# CC1314R10 register map
File version: 1.0
CPU: CM33 1.0, other endian, MPU, FPU, 3 interrupt priority bits
Registers are 32-bit, read-write, reset 0x0 unless marked. A register's access mark holds for its fields unless they carry their own. Offsets are from the block's base; [hi:lo] are bit positions; {n}, {i} and the like mark numbered series.

## AUX_SYSIF — AUX System Interface (AUX_SYSIF) is responsible for: - system resource requests, such as power supply, clock and, wakeup requests. - configuration of AUX peripheral operational rates for AUX_SPIM, AUX_MAC, AUX_ANAIF DAC state machine and AUX_TIMER01. - configuration of event synchronization rate for AUX_EVCTL:EVSTAT2 and AUX_EVCTL:EVSTAT3. - configuration of AUX_SCE wakeup vectors that trigger AUX_SCE execution from sleep. Peripheral operational rate for AUX modules mentioned above can either be: - SCE rate, which is configured in AON_PMCTL:AUXSCECLK. - AUX bus rate, which equals SCE rate or SCLK_HF divided by two when MCU domain is active or AUX operational mode is active. AUX_SYSIF also interfaces AON_RTC and AON_BATMON to enable read access to data and sub-second increment control of AON_RTC.
Base 0x580C6000
0x00 OPMODEREQ — Operational Mode Request AUX can operate in three operational modes. Each mode is associated with: - a SCE clock source or rate, given by AON_PMCTL:AUXSCECLK. This rate is termed SCE_RATE. - a system power supply state request. AUX can request powerdown (uLDO) or active (GLDO or DCDC) system power supply state. - a specific system response to an active AUX wakeup flag. The response is dependent on what operational mode is requested. uLDO power supply state offers limited current supply. AUX_SCE cannot use certain peripherals and functions such as AUX_DDI0_OSC, AUX_TDC and AUX_ANAIF ADC interface in this power supply state. Follow these rules: - It is not allowed to change a request until it has been acknowledged through OPMODEACK. - A change in mode request must happen stepwise along this sequence, the direction is irrelevant: PDA - A - LP - PDLP. Failure to follow these rules might result in unexpected behavior and must be avoided.
  [1:0] REQ — [1:0] AUX operational mode request.
    3=PDLP (Powerdown operational mode with wakeup to lowpower mode, characterized by: - Powerdown system power supply state (uLDO) request. - AON_PMCTL:AUXSCECLK.PD_SRC sets the SCE clock frequency (SCE_RATE). - An active wakeup flag overrides the operational mode externally to lowpower (LP) as long as the flag is set.); 2=PDA (Powerdown operational mode with wakeup to active mode, characterized by: - Powerdown system power supply state (uLDO) request. - AON_PMCTL:AUXSCECLK.PD_SRC sets the SCE clock frequency (SCE_RATE). - An active wakeup flag overrides the operational mode externally to active (A) as long as the flag is set.); 1=LP (Lowpower operational mode, characterized by: - Powerdown system power supply state (uLDO) request. - SCE clock frequency (SCE_RATE) equals SCLK_MF. - An active wakeup flag does not change operational mode.); 0=A (Active operational mode, characterized by: - Active system power supply state (GLDO or DCDC) request. - AON_PMCTL:AUXSCECLK.SRC sets the SCE clock frequency (SCE_RATE). - An active wakeup flag does not change operational mode.)
0x04 OPMODEACK — Operational Mode Acknowledgement AUX_SCE program must assume that the current operational mode is the one acknowledged.
  [1:0] ACK ro — [1:0] AUX operational mode acknowledgement.
    3=PDLP (Powerdown operational mode with wakeup to lowpower mode is acknowledged.); 2=PDA (Powerdown operational mode with wakeup to active mode is acknowledged.); 1=LP (Lowpower operational mode is acknowledged.); 0=A (Active operational mode is acknowledged.)
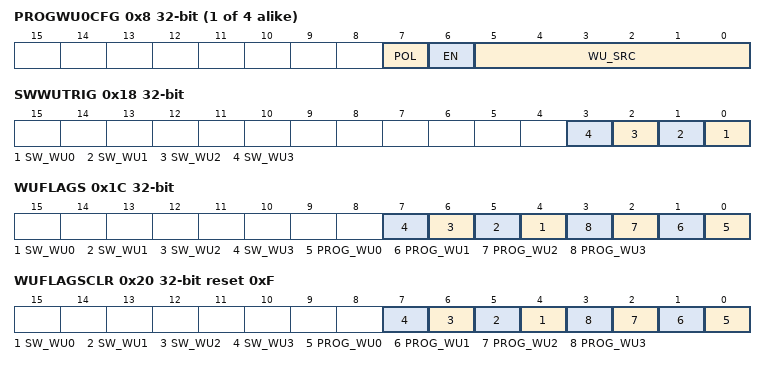
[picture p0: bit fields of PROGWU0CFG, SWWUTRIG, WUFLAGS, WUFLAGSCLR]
{0x8+4i} PROGWU{i}CFG (i=0..3) — Programmable Wakeup {i} Configuration Configure this register to enable a customized AUX wakeup flag. The wakeup flag will be captured by AON_PMCTL which responds according to the current operational mode. You can select WUFLAGS.PROG_WU{i} to trigger execution of a programmable AUX_SCE vector by configuration of VECCFGn. You need to follow the procedure described in WUFLAGSCLR to clear this flag. You need to follow the procedure described in WUGATE to configure it.
  [7] POL — [7:7] Polarity of WU_SRC. The procedure used to clear the wakeup flag decides level or edge sensitivity, see WUFLAGSCLR.PROG_WU{i}.
    1=LOW (The wakeup flag is set when WU_SRC is low or goes low.); 0=HIGH (The wakeup flag is set when WU_SRC is high or goes high.)
  [6] EN — [6:6] Programmable wakeup flag enable. 0: Disable wakeup flag. 1: Enable wakeup flag.
  [5:0] WU_SRC — [5:0] Wakeup source from the asynchronous AUX event bus. Only change WU_SRC when EN is 0 or WUFLAGSCLR.PROG_WU{i} is 1. If you write a non-enumerated value the behavior is identical to NO_EVENT. The written value is returned when read.
    63=NO_EVENT; 61=AUX_SMPH_AUTOTAKE_DONE (AUX_EVCTL:EVSTAT3.AUX_SMPH_AUTOTAKE_DONE); 60=AUX_ADC_FIFO_NOT_EMPTY (AUX_EVCTL:EVSTAT3.AUX_ADC_FIFO_NOT_EMPTY); 59=AUX_ADC_FIFO_ALMOST_FULL (AUX_EVCTL:EVSTAT3.AUX_ADC_FIFO_ALMOST_FULL); 58=AUX_ADC_IRQ (AUX_EVCTL:EVSTAT3.AUX_ADC_IRQ); 57=AUX_ADC_DONE (AUX_EVCTL:EVSTAT3.AUX_ADC_DONE); 56=AUX_ISRC_RESET_N (AUX_EVCTL:EVSTAT3.AUX_ISRC_RESET_N); 55=AUX_TDC_DONE (AUX_EVCTL:EVSTAT3.AUX_TDC_DONE); 54=AUX_TIMER0_EV (AUX_EVCTL:EVSTAT3.AUX_TIMER0_EV); 53=AUX_TIMER1_EV (AUX_EVCTL:EVSTAT3.AUX_TIMER1_EV); 52=AUX_TIMER2_PULSE (AUX_EVCTL:EVSTAT3.AUX_TIMER2_PULSE); {v}=AUX_TIMER2_EV{v-48} (AUX_EVCTL:EVSTAT3.AUX_TIMER2_EV{v-48}) (v=48..51); 47=AUX_COMPB (AUX_EVCTL:EVSTAT2.AUX_COMPB); 46=AUX_COMPA (AUX_EVCTL:EVSTAT2.AUX_COMPA); 45=MCU_OBSMUX1 (AUX_EVCTL:EVSTAT2.MCU_OBSMUX1); 44=MCU_OBSMUX0 (AUX_EVCTL:EVSTAT2.MCU_OBSMUX0); 43=MCU_EV (AUX_EVCTL:EVSTAT2.MCU_EV); 42=ACLK_REF (AUX_EVCTL:EVSTAT2.ACLK_REF); 41=VDDR_RECHARGE (AUX_EVCTL:EVSTAT2.VDDR_RECHARGE); 40=MCU_ACTIVE (AUX_EVCTL:EVSTAT2.MCU_ACTIVE); 39=PWR_DWN (AUX_EVCTL:EVSTAT2.PWR_DWN); 38=SCLK_LF (AUX_EVCTL:EVSTAT2.SCLK_LF); 37=AON_BATMON_TEMP_UPD (AUX_EVCTL:EVSTAT2.AON_BATMON_TEMP_UPD); 36=AON_BATMON_BAT_UPD (AUX_EVCTL:EVSTAT2.AON_BATMON_BAT_UPD); 35=AON_RTC_4KHZ (AUX_EVCTL:EVSTAT2.AON_RTC_4KHZ); 34=AON_RTC_CH2_DLY (AUX_EVCTL:EVSTAT2.AON_RTC_CH2_DLY); 33=AON_RTC_CH2 (AUX_EVCTL:EVSTAT2.AON_RTC_CH2); 32=MANUAL_EV (AUX_EVCTL:EVSTAT2.MANUAL_EV); {v}=AUXIO{v} (AUX_EVCTL:EVSTAT1.AUXIO{v}) (v=16..31); {v}=AUXIO{v} (AUX_EVCTL:EVSTAT0.AUXIO{v}) (v=0..15)
0x18 SWWUTRIG — Software Wakeup Triggers System CPU uses these wakeup flags to perform handshaking with AUX_SCE. The wakeup flags can change the operational mode of AUX and guarantees a non-zero SCE clock rate. AUX_SCE wakeup vectors are configured in VECCFGn.
  [n] SW_WU{n} wo (n=0..3) — [{n}:{n}] Software wakeup {n} trigger. 0: No effect. 1: Set WUFLAGS.SW_WU{n} and trigger AUX wakeup.
0x1C WUFLAGS — Wakeup Flags This register holds the eight AUX wakeup flags. Each flag can cause AUX operational mode to change as given in OPMODEREQ. To clear flag n you must set bit n in WUFLAGSCLR until flag n is read as 0. You must clear bit n in WUFLAGSCLR before flag n can be set again.
  [n+4] SW_WU{n} ro (n=0..3) — [{n+4}:{n+4}] Software wakeup {n} flag. 0: Software wakeup {n} not triggered. 1: Software wakeup {n} triggered.
  [n] PROG_WU{n} ro (n=0..3) — [{n}:{n}] Programmable wakeup {n}. 0: Programmable wakeup {n} not triggered. 1: Programmable wakeup {n} triggered.
0x20 WUFLAGSCLR reset 0xF — Wakeup Flags Clear This register clears AUX wakeup flags WUFLAGS. To clear programmable wakeup flags you must disable the AUX wakeup output first. After the programmable wakeup flags are cleared you must re-enable the AUX wakeup output. Write WUGATE to disable or enable the AUX wakeup output. This procedure is not required when you want to clear a software-triggered wakeup.
  [n+4] SW_WU{n} (n=0..3) — [{n+4}:{n+4}] Clear software wakeup flag {n}. 0: No effect. 1: Clear WUFLAGS.SW_WU{n}. Keep high until WUFLAGS.SW_WU{n} is 0.
  [n] PROG_WU{n} (n=0..3) — [{n}:{n}] Programmable wakeup flag {n}. 0: No effect. 1: Clear WUFLAGS.PROG_WU{n}. Keep high until WUFLAGS.PROG_WU{n} is 0. The wakeup flag becomes edge sensitive if you write PROG_WU{n} to 0 when PROGWU{n}CFG.EN is 1. The wakeup flag becomes level sensitive if you write PROG_WU{n} to 0 when PROGWU{n}CFG.EN is 0, then set PROGWU{n}CFG.EN.
0x24 WUGATE — Wakeup Gate You must disable the AUX wakeup output: - Before you clear a programmable wakeup flag. - Before you change the value of [PROGWUnCFG.EN] or [PROGWUnCFG.WU_SRC]. The AUX wakeup output must be re-enabled after clear operation or programmable wakeup configuration.
  [0] EN — [0:0] Wakeup output enable. 0: Disable AUX wakeup output. 1: Enable AUX wakeup output.
{0x28+4i} VECCFG{i} (i=0..7) — Vector Configuration {i} AUX_SCE wakeup vector {i} configuration
  [3:0] VEC_EV — [3:0] Select trigger event for vector {i}. Non-enumerated values are treated as NONE.
    9=AON_RTC_CH2_DLY (AUX_EVCTL:EVSTAT2.AON_RTC_CH2_DLY); {v}=SW_WU{v-5} (WUFLAGS.SW_WU{v-5}) (v=5..8); {v}=PROG_WU{v-1} (WUFLAGS.PROG_WU{v-1}) (v=1..4); 0=NONE (Vector is disabled.)
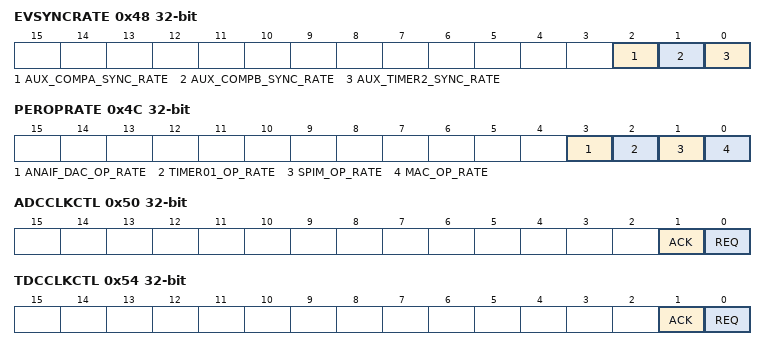
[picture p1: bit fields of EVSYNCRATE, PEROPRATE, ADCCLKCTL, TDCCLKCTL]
0x48 EVSYNCRATE — Event Synchronization Rate Configure synchronization rate for certain events to the synchronous AUX event bus. You must select SCE rate when AUX_SCE uses the event. You must select AUX bus rate when system CPU uses the event. SCE rate equals rate configured in AON_PMCTL:AUXSCECLK. AUX bus rate equals SCE rate, or SCLK_HF divided by two when MCU domain is active.
  [all] fields
    1=BUS_RATE (AUX bus rate); 0=SCE_RATE
  [2] AUX_COMPA_SYNC_RATE — [2:2] Select synchronization rate for AUX_EVCTL:EVSTAT2.AUX_COMPA event.
  [1] AUX_COMPB_SYNC_RATE — [1:1] Select synchronization rate for AUX_EVCTL:EVSTAT2.AUX_COMPB event.
  [0] AUX_TIMER2_SYNC_RATE — [0:0] Select synchronization rate for: - AUX_EVCTL:EVSTAT3.AUX_TIMER2_EV0 - AUX_EVCTL:EVSTAT3.AUX_TIMER2_EV1 - AUX_EVCTL:EVSTAT3.AUX_TIMER2_EV2 - AUX_EVCTL:EVSTAT3.AUX_TIMER2_EV3 - AUX_EVCTL:EVSTAT3.AUX_TIMER2_PULSE
0x4C PEROPRATE — Peripheral Operational Rate Some AUX peripherals are operated at either SCE or at AUX bus rate. You must select SCE rate when AUX_SCE uses such peripheral or an event produced by it. You must select AUX bus rate when system CPU uses such peripheral. SCE rate equals rate configured in AON_PMCTL:AUXSCECLK. AUX bus rate equals SCE rate, or SCLK_HF divided by 2 when MCU domain is active.
  [all] fields
    1=BUS_RATE (AUX bus rate); 0=SCE_RATE
  [3] ANAIF_DAC_OP_RATE — [3:3] Select operational rate for AUX_ANAIF DAC sample clock state machine.
  [2] TIMER01_OP_RATE — [2:2] Select operational rate for AUX_TIMER01.
  [1] SPIM_OP_RATE — [1:1] Select operational rate for AUX_SPIM.
  [0] MAC_OP_RATE — [0:0] Select operational rate for AUX_MAC.
0x50 ADCCLKCTL — ADC Clock Control
  [1] ACK ro — [1:1] Clock acknowledgement. 0: ADC clock is disabled. 1: ADC clock is enabled.
  [0] REQ — [0:0] ADC clock request. 0: Disable ADC clock. 1: Enable ADC clock. Only modify REQ when equal to ACK.
0x54 TDCCLKCTL — TDC Counter Clock Control Controls if the AUX_TDC counter clock source is enabled. These are the recommended steps to configure and request the counter clock: - Ensure that REQ=0 and ACK=0. - Configure clock source in DDI_0_OSC:CTL0.ACLK_TDC_SRC_SEL. - Read DDI_0_OSC:CTL0 to avoid a race condition between previous step and next step. - Set REQ=1 to request the clock. - If DDI_0_OSC:CTL0.ACLK_TDC_SRC_SEL=RCOSC_HF (24 or 48 MHz), wait until ACK=1. - If DDI_0_OSC:CTL0.ACLK_TDC_SRC_SEL=XOSC_HF, wait until ACK=1 and DDI_0_OSC:STAT2.XOSC_HF_FREQGOOD=1. After these steps ACK stays high until REQ=0. It is hence not recommended to reconfigure DDI_0_OSC:CTL0.ACLK_TDC_SRC_SEL when ACK=1. In this case, there will be no indication of when the new clock source selection is ready. These are the recommended steps to stop the counter clock: - Ensure that REQ=1 and ACK=1. - Set REQ=0 to stop the clock. - Wait until ACK=0.
  [1] ACK ro — [1:1] TDC counter clock acknowledgement. 0: TDC counter clock is disabled. 1: TDC counter clock is enabled.
  [0] REQ — [0:0] TDC counter clock request. 0: Disable TDC counter clock. 1: Enable TDC counter clock. Only modify REQ when equal to ACK.
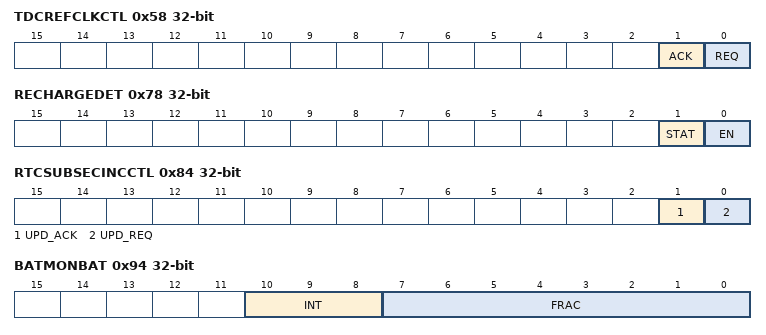
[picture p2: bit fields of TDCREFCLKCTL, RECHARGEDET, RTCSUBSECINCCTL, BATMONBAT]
0x58 TDCREFCLKCTL — TDC Reference Clock Control Controls if the AUX_TDC reference clock source is enabled. These are the recommended steps to configure and request the reference clock: - Ensure that REQ=0 and ACK=0. - Configure clock source in DDI_0_OSC:CTL0.ACLK_REF_SRC_SEL. - Read DDI_0_OSC:CTL0 to avoid a race condition between previous step and next step. - Set REQ=1 to request the clock. - Wait until ACK=1. After these steps ACK stays high until REQ=0. It is hence not recommended to reconfigure DDI_0_OSC:CTL0.ACLK_REF_SRC_SEL when ACK=1. In this case, there will be no indication of when the new clock source selection is ready. These are the recommended steps to stop the reference clock: - Ensure that REQ=1 and ACK=1. - Set REQ=0 to stop the clock. - Wait until ACK=0. It is not recommended to enable the TDC reference clock if DDI_0_OSC:CTL0.SCLK_LF_SRC_SEL=RCOSCHFDLF (0x0).
  [1] ACK ro — [1:1] TDC reference clock acknowledgement. 0: TDC reference clock is disabled. 1: TDC reference clock is enabled.
  [0] REQ — [0:0] TDC reference clock request. 0: Disable TDC reference clock. 1: Enable TDC reference clock. Only modify REQ when equal to ACK.
0x5C TIMER2CLKCTL — AUX_TIMER2 Clock Control Access to AUX_TIMER2 is only possible when TIMER2CLKSTAT.STAT is different from NONE.
  [2:0] SRC — [2:0] Select clock source for AUX_TIMER2. Update is only accepted if SRC equals TIMER2CLKSTAT.STAT or TIMER2CLKSWITCH.RDY is 1. It is recommended to select NONE only when TIMER2BRIDGE.BUSY is 0. A non-enumerated value is ignored.
    4=SCLK_HFDIV2 (SCLK_HF / 2); 2=SCLK_MF; 1=SCLK_LF; 0=NONE (no clock)
0x60 TIMER2CLKSTAT — AUX_TIMER2 Clock Status
  [2:0] STAT ro — [2:0] AUX_TIMER2 clock source status.
    4=SCLK_HFDIV2 (SCLK_HF / 2); 2=SCLK_MF; 1=SCLK_LF; 0=NONE (No clock)
0x64 TIMER2CLKSWITCH reset 0x1 — AUX_TIMER2 Clock Switch
  [0] RDY ro — [0:0] Status of clock switcher. 0: TIMER2CLKCTL.SRC is different from TIMER2CLKSTAT.STAT. 1: TIMER2CLKCTL.SRC equals TIMER2CLKSTAT.STAT. RDY connects to AUX_EVCTL:EVSTAT3.AUX_TIMER2_CLKSWITCH_RDY.
0x68 TIMER2DBGCTL — AUX_TIMER2 Debug Control
  [0] DBG_FREEZE_EN — [0:0] Debug freeze enable. 0: AUX_TIMER2 does not halt when the system CPU halts in debug mode. 1: Halt AUX_TIMER2 when the system CPU halts in debug mode.
0x70 CLKSHIFTDET reset 0x1 — Clock Shift Detection A transition in the MCU domain state causes a non-accumulative change to the SCE clock period when the AUX clock rate is derived from SCLK_MF or SCLK_LF: - A single SCE clock cycle is 6 thru 8 SCLK_HF cycles longer when MCU domain enters active state. - A single SCE clock cycle is 6 thru 8 SCLK_HF cycles shorter when MCU domain exits active state. AUX_SCE detects if such events occurred to the SCE clock during the time period between a clear of STAT and a read of STAT.
  [0] STAT — [0:0] Clock shift detection. Write: 0: Restart clock shift detection. 1: Do not use. Read: 0: MCU domain did not enter or exit active state since you wrote 0 to STAT. 1: MCU domain entered or exited active state since you wrote 0 to STAT.
0x74 RECHARGETRIG — VDDR Recharge Trigger
  [0] TRIG — [0:0] Recharge trigger. 0: No effect. 1: Request VDDR recharge. Request VDDR recharge only when AUX_EVCTL:EVSTAT2.PWR_DWN is 1. Follow this sequence when OPMODEREQ.REQ is LP: - Set TRIG. - Wait until AUX_EVCTL:EVSTAT2.VDDR_RECHARGE is 1. - Clear TRIG. - Wait until AUX_EVCTL:EVSTAT2.VDDR_RECHARGE is 0. Follow this sequence when OPMODEREQ.REQ is PDA or PDLP: - Set TRIG. - Clear TRIG.
0x78 RECHARGEDET — VDDR Recharge Detection Some applications can be sensitive to power noise caused by recharge of VDDR. You can detect if VDDR recharge occurs.
  [1] STAT ro — [1:1] VDDR recharge detector status. 0: No recharge of VDDR has occurred since EN was set. 1: Recharge of VDDR has occurred since EN was set.
  [0] EN — [0:0] VDDR recharge detector enable. 0: Disable recharge detection. STAT becomes zero. 1: Enable recharge detection.
0x7C RTCSUBSECINC0 — Real Time Counter Sub Second Increment 0 INC15_0 will replace bits 15:0 in AON_RTC:SUBSECINC when RTCSUBSECINCCTL.UPD_REQ is set. AUX_SCE is not allowed to access this register when system state is secure. Any access will suspend the AUX_SCE.
  [15:0] INC15_0 — [15:0] New value for bits 15:0 in AON_RTC:SUBSECINC.
0x80 RTCSUBSECINC1 — Real Time Counter Sub Second Increment 1 INC23_16 will replace bits 23:16 in AON_RTC:SUBSECINC when RTCSUBSECINCCTL.UPD_REQ is set. AUX_SCE is not allowed to access this register when system state is secure. Any access will suspend the AUX_SCE.
  [7:0] INC23_16 — [7:0] New value for bits 23:16 in AON_RTC:SUBSECINC.
0x84 RTCSUBSECINCCTL — Real Time Counter Sub Second Increment Control AUX_SCE is not allowed to access this register when system state is secure. Any access will suspend the AUX_SCE.
  [1] UPD_ACK ro — [1:1] Update acknowledgement. 0: AON_RTC has not acknowledged UPD_REQ. 1: AON_RTC has acknowledged UPD_REQ.
  [0] UPD_REQ — [0:0] Request AON_RTC to update AON_RTC:SUBSECINC. 0: Clear request to update. 1: Set request to update. Only change UPD_REQ when it equals UPD_ACK. Clear UPD_REQ after UPD_ACK is 1.
0x88 RTCSEC — Real Time Counter Second System CPU must not access this register. Instead, system CPU must access AON_RTC:SEC.VALUE directly.
  [15:0] SEC ro — [15:0] Bits 15:0 in AON_RTC:SEC.VALUE. Follow this procedure to get the correct value: - Do two dummy reads of SEC. - Then read SEC until two consecutive reads are equal.
0x8C RTCSUBSEC — Real Time Counter Sub-Second System CPU must not access this register. Instead, system CPU must access AON_RTC:SUBSEC.VALUE directly.
  [15:0] SUBSEC ro — [15:0] Bits 31:16 in AON_RTC:SUBSEC.VALUE. Follow this procedure to get the correct value: - Do two dummy reads SUBSEC. - Then read SUBSEC until two consecutive reads are equal.
0x90 RTCEVCLR — AON_RTC Event Clear Request to clear events: - AON_RTC:EVFLAGS.CH2. - AON_RTC:EVFLAGS.CH2 delayed version. - AUX_EVCTL:EVSTAT2.AON_RTC_CH2. - AUX_EVCTL:EVSTAT2.AON_RTC_CH2_DLY.
  [0] RTC_CH2_EV_CLR — [0:0] Clear events from AON_RTC channel 2. 0: No effect. 1: Clear events from AON_RTC channel 2. Keep RTC_CH2_EV_CLR high until AUX_EVCTL:EVSTAT2.AON_RTC_CH2 and AUX_EVCTL:EVSTAT2.AON_RTC_CH2_DLY are 0.
0x94 BATMONBAT — AON_BATMON Battery Voltage Value Read access to AON_BATMON:BAT. System CPU must not access this register. Instead, system CPU must access AON_BATMON:BAT directly. AON_BATMON:BAT updates during VDDR recharge or active operational mode.
  [10:8] INT ro — [10:8] See AON_BATMON:BAT.INT. Follow this procedure to get the correct value: - Do two dummy reads of INT. - Then read INT until two consecutive reads are equal.
  [7:0] FRAC ro — [7:0] See AON_BATMON:BAT.FRAC. Follow this procedure to get the correct value: - Do two dummy reads of FRAC. - Then read FRAC until two consecutive reads are equal.
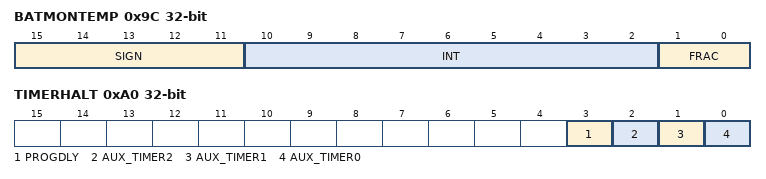
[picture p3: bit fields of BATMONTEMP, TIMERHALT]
0x9C BATMONTEMP — AON_BATMON Temperature Value Read access to AON_BATMON:TEMP. System CPU must not access this register. Instead, system CPU must access AON_BATMON:TEMP directly. AON_BATMON:TEMP updates during VDDR recharge or active operational mode.
  [15:11] SIGN ro — [15:11] Sign extension of INT. Follow this procedure to get the correct value: - Do two dummy reads of SIGN. - Then read SIGN until two consecutive reads are equal.
  [10:2] INT ro — [10:2] See AON_BATMON:TEMP.INT. Follow this procedure to get the correct value: - Do two dummy reads of INT. - Then read INT until two consecutive reads are equal.
  [1:0] FRAC ro — [1:0] See AON_BATMON:TEMP.FRAC. Follow this procedure to get the correct value: - Do two dummy reads of FRAC. - Then read FRAC until two consecutive reads are equal.
0xA0 TIMERHALT — Timer Halt Debug register
  [3] PROGDLY — [3:3] Halt programmable delay. 0: AUX_EVCTL:PROGDLY.VALUE decrements as normal. 1: Halt AUX_EVCTL:PROGDLY.VALUE decrementation.
  [2] AUX_TIMER2 — [2:2] Halt AUX_TIMER2. 0: AUX_TIMER2 operates as normal. 1: Halt AUX_TIMER2 operation.
  [1] AUX_TIMER1 — [1:1] Halt AUX_TIMER01 Timer 1. 0: AUX_TIMER01 Timer 1 operates as normal. 1: Halt AUX_TIMER01 Timer 1 operation.
  [0] AUX_TIMER0 — [0:0] Halt AUX_TIMER01 Timer 0. 0: AUX_TIMER01 Timer 0 operates as normal. 1: Halt AUX_TIMER01 Timer 0 operation.
0xB0 TIMER2BRIDGE — AUX_TIMER2 Bridge
  [0] BUSY ro — [0:0] Status of bus transactions to AUX_TIMER2. 0: No unfinished bus transactions. 1: A bus transaction is ongoing.
0xB4 SWPWRPROF — Software Power Profiler
  [2:0] STAT — [2:0] Software status bits that can be read by the power profiler.
